# Montana register map
Vendor: ONSemiconductor; Series: Montana Series; File version: 1.0
CPU: CM33 r0p4, little endian, MPU, FPU, 3 interrupt priority bits
Registers are 32-bit, read-write, reset 0x0 unless marked. A register's access mark holds for its fields unless they carry their own. Offsets are from the block's base; [hi:lo] are bit positions; {n}, {i} and the like mark numbered series.

## LSAD — Low-Speed ADC
Base 0x40001500
{0x0+4i} LSAD_DATA_TRIM_CH[{i}] (i=0..7) ro — LSAD conversion result for channel 0 to 7 in trimmer mode
  [13:0] DATA — 14-bit LSAD conversion result
{0x20+4i} LSAD_DATA_AUDIO_CH[{i}] (i=0..7) ro — LSAD conversion result for channel 0 to 7 in audio mode (signed)
  [31:0] DATA — 14-bit LSAD conversion result (sign extended to 32 bits)
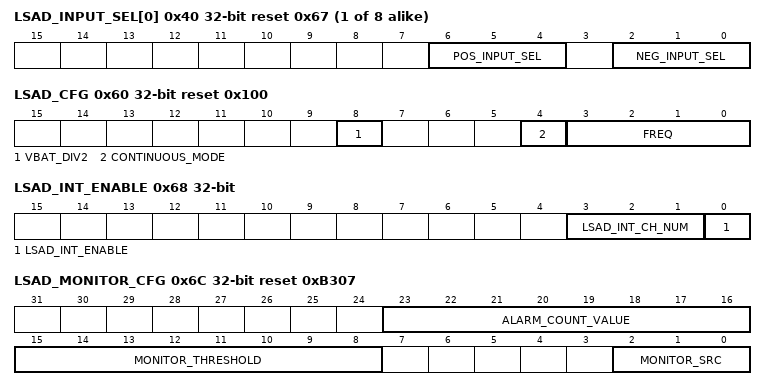
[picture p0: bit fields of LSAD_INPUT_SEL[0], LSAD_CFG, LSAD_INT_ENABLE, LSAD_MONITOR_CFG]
{0x40+4i} LSAD_INPUT_SEL[{i}] (i=0..7) reset 0x67 — LSAD input selection for channel 0 to 7
  [6:4] POS_INPUT_SEL — Positive input selection
    {v}=LSAD_POS_INPUT_SEL{v} (Select pre-selection input {v} as positive input) (v=0..3); 4=LSAD_POS_INPUT_AOUT (Select AOUT as positive input); 5=LSAD_POS_INPUT_TEMP (Select temperature sensor as positive input); 6=LSAD_POS_INPUT_VBAT (Select VBAT or VBAT/2 as positive input); 7=LSAD_POS_INPUT_GND (Select LSAD internal ground as positive input)
  [2:0] NEG_INPUT_SEL — Negative input selection
    {v}=LSAD_NEG_INPUT_SEL{v} (Select pre-selection input {v} as negative input) (v=0..3); 4=LSAD_NEG_INPUT_AOUT (Select AOUT as negative input); 5=LSAD_NEG_INPUT_TEMP (Select temperature as negative input); 6=LSAD_NEG_INPUT_VBAT (Select VBAT or VBAT/2 as negative input); 7=LSAD_NEG_INPUT_GND (Select LSAD internal ground as negative input)
0x60 LSAD_CFG reset 0x100 — LSAD Configuration Register
  [8] VBAT_DIV2
    0=VBAT_DIV2_DISABLE (The VBAT voltage divider is disabled); 1=VBAT_DIV2_ENABLE (The VBAT voltage divider is enabled (VBAT/2))
  [4] CONTINUOUS_MODE — LSAD continuously sampling the channel selected as interrupt source (LSAD_INT_CH_NUM)
    0=LSAD_NORMAL (Normal mode, all 8 channels sampled); 1=LSAD_CONTINUOUS (Continuous mode: only one channel sampled (for test purpose))
  [3:0] FREQ — Defines the sampling frequency of the LSAD channels
    0=LSAD_DISABLE (LSAD disabled); 1=LSAD_PRESCALE_200 (Sample rate is SLOWCLK/200 (low speed mode)); 2=LSAD_PRESCALE_400 (Sample rate is SLOWCLK/400 (low speed mode)); 3=LSAD_PRESCALE_640 (Sample rate is SLOWCLK/640 (low speed mode)); 4=LSAD_PRESCALE_800 (Sample rate is SLOWCLK/800 (low speed mode)); 5=LSAD_PRESCALE_1600 (Sample rate is SLOWCLK/1600 (low speed mode)); 6=LSAD_PRESCALE_3200 (Sample rate is SLOWCLK/3200 (low speed mode)); 7=LSAD_PRESCALE_6400 (Sample rate is SLOWCLK/6400 (low speed mode)); 8=LSAD_PRESCALE_20H (Sample rate is SLOWCLK/20 (high speed mode)); 9=LSAD_PRESCALE_40H (Sample rate is SLOWCLK/40 (high speed mode)); 10=LSAD_PRESCALE_80H (Sample rate is SLOWCLK/80 (high speed mode)); 11=LSAD_PRESCALE_128H (Sample rate is SLOWCLK/128 (high speed mode)); 12=LSAD_PRESCALE_160H (Sample rate is SLOWCLK/160 (high speed mode)); 13=LSAD_PRESCALE_320H (Sample rate is SLOWCLK/320 (high speed mode)); 14=LSAD_PRESCALE_640H (Sample rate is SLOWCLK/640 (high speed mode)); 15=LSAD_PRESCALE_1280H (Sample rate is SLOWCLK/1280 (high speed mode))
0x64 LSAD_OFFSET — LSAD conversion result for LSAD GND
  [14:0] DATA — 15-bit LSAD signed offset
0x68 LSAD_INT_ENABLE — LSAD Interrupt Mask Register
  [3:1] LSAD_INT_CH_NUM — Channel number triggering the LSAD interrupt
    {v}=LSAD_INT_CH{v} (The LSAD interrupt is triggered when the LSAD_DATA_CH{v} register is updated) (v=0..7)
  [0] LSAD_INT_ENABLE — The LSAD new sample ready interrupt mask
    0=LSAD_INT_DIS (This source cannot set an interrupt); 1=LSAD_INT_EN (This source can set the LSAD interrupt line)
0x6C LSAD_MONITOR_CFG reset 0xB307 — Monitoring Configuration Register
  [23:16] ALARM_COUNT_VALUE — An Alarm Status bit is set and an interrupt generated when SUPPLY_COUNT_VALUE = ALARM_COUNT_VALUE
    0=MONITOR_ALARM_NONE (No Alarm is triggered); 1=MONITOR_ALARM_COUNT1 (Alarm count value is 1); 255=MONITOR_ALARM_COUNT255 (Alarm count value is 255)
  [15:8] MONITOR_THRESHOLD — Low voltage detection threshold (7.8 mV steps)
    0=MONITOR_THRESHOLD_LOW (Lowest voltage threshold: 7.8 mV); 179=MONITOR_THRESHOLD_MID (Mid voltage threshold: 1.4 V); 255=MONITOR_THRESHOLD_HIGH (Highest voltage threshold: ~2.0 V)
  [2:0] MONITOR_SRC — Selects the source channel to be monitored
    {v}=MONITOR_CH{v} (Channel {v} is monitored) (v=0..7)
0x70 LSAD_MONITOR_COUNT_VAL ro — Monitoring Status Register
  [7:0] MONITOR_COUNT_VALUE — Number of times the voltage has fallen below the monitor voltage threshold. The counter is reset when read.
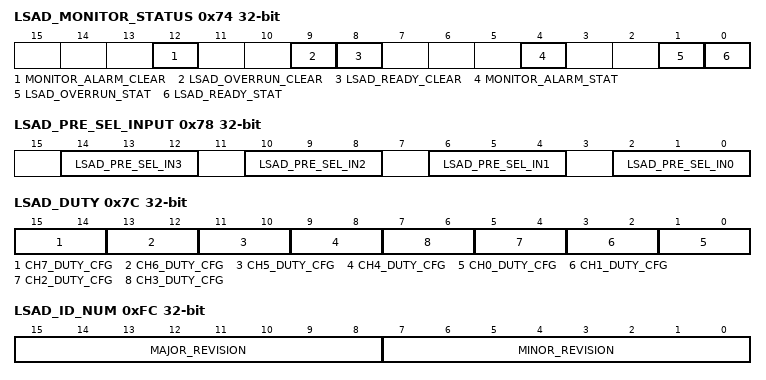
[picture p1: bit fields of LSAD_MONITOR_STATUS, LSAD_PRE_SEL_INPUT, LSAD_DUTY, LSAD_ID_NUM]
0x74 LSAD_MONITOR_STATUS (reset mask 0x13)
  [12] MONITOR_ALARM_CLEAR wo — Monitoring alarm status bit
    1=MONITOR_ALARM_CLEAR (Writing a 1 clears the MONITOR Alarm status bit)
  [9] LSAD_OVERRUN_CLEAR wo — LSAD Overrun condition
    1=LSAD_OVERRUN_CLEAR (Writing a 1 clears the LSAD Overrun status bit)
  [8] LSAD_READY_CLEAR wo — LSAD new sample Ready status bit
    1=LSAD_READY_CLEAR (Writing a 1 clears the LSAD Ready status bit)
  [4] MONITOR_ALARM_STAT ro — Monitoring alarm status bit
    0=MONITOR_ALARM_FALSE (MONITOR Alarm flag not set); 1=MONITOR_ALARM_TRUE (MONITOR Alarm has been triggered)
  [1] LSAD_OVERRUN_STAT ro — LSAD Overrun condition
    0=LSAD_OVERRUN_FALSE (No LSAD Overrun detected); 1=LSAD_OVERRUN_TRUE (LSAD Overrun detected)
  [0] LSAD_READY_STAT ro — LSAD new sample Ready status bit
    0=LSAD_READY_FALSE (No new LSAD samples available); 1=LSAD_READY_TRUE (New LSAD samples are ready)
0x78 LSAD_PRE_SEL_INPUT — LSAD pre-selection for input 0
  [14:12] LSAD_PRE_SEL_IN3 — LSAD input pre-selection
    0=IN3_PRE_SEL_GPIO1 (GPIO1 pre-selected for lsad input 3); 1=IN3_PRE_SEL_GPIO3 (GPIO3 pre-selected for lsad input 3); 2=IN3_PRE_SEL_GPIO5 (GPIO5 pre-selected for lsad input 3); 3=IN3_PRE_SEL_GPIO7 (GPIO7 pre-selected for lsad input 3); 4=IN3_PRE_SEL_GPIO9 (GPIO9 pre-selected for lsad input 3); 5=IN3_PRE_SEL_GPIO11 (GPIO11 pre-selected for lsad input 3); 6=IN3_PRE_SEL_GPIO13 (GPIO13 pre-selected for lsad input 3); 7=IN3_PRE_SEL_GPIO15 (GPIO15 pre-selected for lsad input 3)
  [10:8] LSAD_PRE_SEL_IN2 — LSAD input pre-selection
    0=IN2_PRE_SEL_GPIO0 (GPIO0 pre-selected for lsad input 2); 1=IN2_PRE_SEL_GPIO2 (GPIO2 pre-selected for lsad input 2); 2=IN2_PRE_SEL_GPIO4 (GPIO4 pre-selected for lsad input 2); 3=IN2_PRE_SEL_GPIO6 (GPIO6 pre-selected for lsad input 2); 4=IN2_PRE_SEL_GPIO8 (GPIO8 pre-selected for lsad input 2); 5=IN2_PRE_SEL_GPIO10 (GPIO10 pre-selected for lsad input 2); 6=IN2_PRE_SEL_GPIO12 (GPIO12 pre-selected for lsad input 2); 7=IN2_PRE_SEL_GPIO14 (GPIO14 pre-selected for lsad input 2)
  [6:4] LSAD_PRE_SEL_IN1 — LSAD input pre-selection
    0=IN1_PRE_SEL_GPIO1 (GPIO1 pre-selected for lsad input 1); 1=IN1_PRE_SEL_GPIO3 (GPIO3 pre-selected for lsad input 1); 2=IN1_PRE_SEL_GPIO5 (GPIO5 pre-selected for lsad input 1); 3=IN1_PRE_SEL_GPIO7 (GPIO7 pre-selected for lsad input 1); 4=IN1_PRE_SEL_GPIO9 (GPIO9 pre-selected for lsad input 1); 5=IN1_PRE_SEL_GPIO11 (GPIO11 pre-selected for lsad input 1); 6=IN1_PRE_SEL_GPIO13 (GPIO13 pre-selected for lsad input 1); 7=IN1_PRE_SEL_GPIO15 (GPIO15 pre-selected for lsad input 1)
  [2:0] LSAD_PRE_SEL_IN0 — LSAD input pre-selection
    0=IN0_PRE_SEL_GPIO0 (GPIO0 pre-selected for lsad input 0); 1=IN0_PRE_SEL_GPIO2 (GPIO2 pre-selected for lsad input 0); 2=IN0_PRE_SEL_GPIO4 (GPIO4 pre-selected for lsad input 0); 3=IN0_PRE_SEL_GPIO6 (GPIO6 pre-selected for lsad input 0); 4=IN0_PRE_SEL_GPIO8 (GPIO8 pre-selected for lsad input 0); 5=IN0_PRE_SEL_GPIO10 (GPIO10 pre-selected for lsad input 0); 6=IN0_PRE_SEL_GPIO12 (GPIO12 pre-selected for lsad input 0); 7=IN0_PRE_SEL_GPIO14 (GPIO14 pre-selected for lsad input 0)
0x7C LSAD_DUTY — LSAD duty config
  [15:14] CH7_DUTY_CFG — Input to channel 7 duty config
    0=INPUT_TO_CH7_PERMANENT (Input always connected to channel); 1=INPUT_TO_CH7_DUTY (Input only connected to the channel during his conversion); 2=INPUT_TO_CH7_RESERVED (reserved - same as 0x0); 3=INPUT_TO_CH7_PRE_CONV (Input connected to the channel during his conversion and the previous conversion)
  [13:12] CH6_DUTY_CFG — Input to channel 6 duty config
    0=INPUT_TO_CH6_PERMANENT (Input always connected to channel); 1=INPUT_TO_CH6_DUTY (Input only connected to the channel during his conversion); 2=INPUT_TO_CH6_RESERVED (reserved - same as 0x0); 3=INPUT_TO_CH6_PRE_CONV (Input connected to the channel during his conversion and the previous conversion)
  [11:10] CH5_DUTY_CFG — Input to channel 5 duty config
    0=INPUT_TO_CH5_PERMANENT (Input always connected to channel); 1=INPUT_TO_CH5_DUTY (Input only connected to the channel during his conversion); 2=INPUT_TO_CH5_RESERVED (reserved - same as 0x0); 3=INPUT_TO_CH5_PRE_CONV (Input connected to the channel during his conversion and the previous conversion)
  [9:8] CH4_DUTY_CFG — Input to channel 4 duty config
    0=INPUT_TO_CH4_PERMANENT (Input always connected to channel); 1=INPUT_TO_CH4_DUTY (Input only connected to the channel during his conversion); 2=INPUT_TO_CH4_RESEREVED (reserved - same as 0x0); 3=INPUT_TO_CH4_PRE_CONV (Input connected to the channel during his conversion and the previous conversion)
  [2n+1:2n] CH{n}_DUTY_CFG (n=0..3) — Input to channel {n} duty config
    0=INPUT_TO_CH{n}_PERMANENT (Input always connected to channel); 1=INPUT_TO_CH{n}_DUTY (Input only connected to the channel during his conversion); 2=INPUT_TO_CH{n}_RESERVED (reserved - same as 0x0); 3=INPUT_TO_CH{n}_PRE_CONV (Input connected to the channel during his conversion and the previous conversion)
0xFC LSAD_ID_NUM ro — LSAD ID Number
  [15:8] MAJOR_REVISION — LSAD Major Revision number
    1=LSAD_MAJOR_REVISION
  [7:0] MINOR_REVISION — LSAD Minor Revision number
    0=LSAD_MINOR_REVISION
